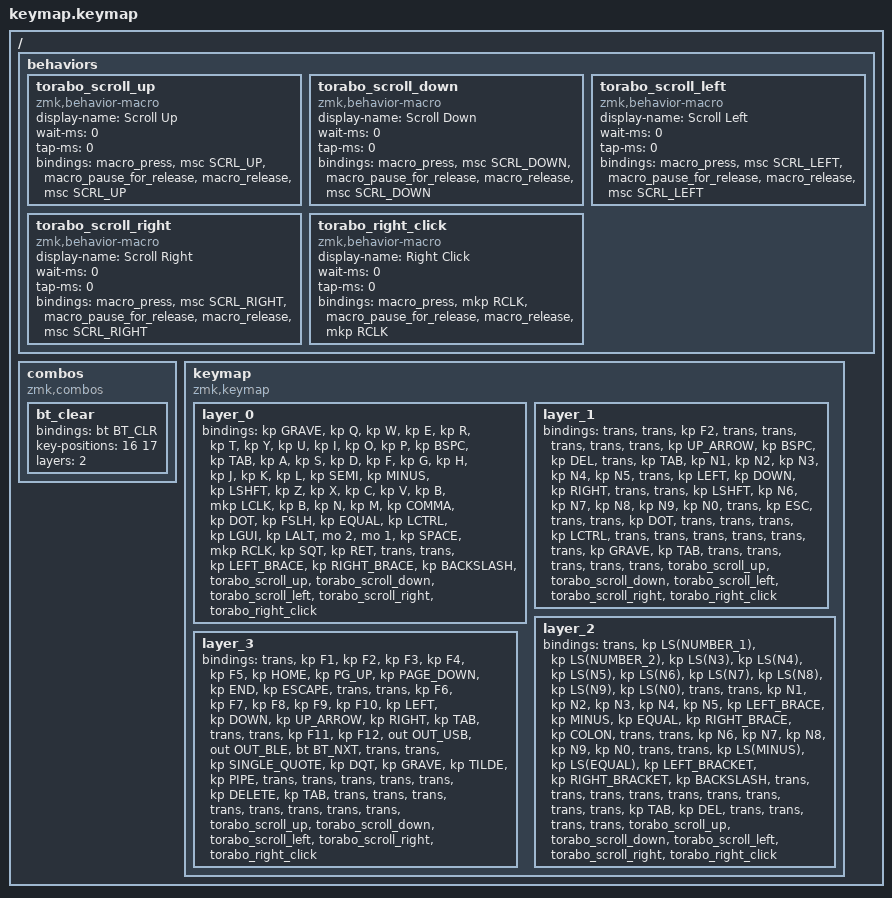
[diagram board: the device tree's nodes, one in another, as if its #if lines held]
#if defined(TORABO_TSUKI_LP_KSCAN_4_DIRECTION_SWITCH)
// Three times the ZMK v0.3 default scroll speed of 10.
#define ZMK_POINTING_DEFAULT_SCRL_VAL 30
#endif

#include <behaviors.dtsi>
#include <dt-bindings/zmk/bt.h>
#include <dt-bindings/zmk/keys.h>
#include <dt-bindings/zmk/outputs.h>
#include <dt-bindings/zmk/pointing.h>

/ {
#if defined(TORABO_TSUKI_LP_KSCAN_4_DIRECTION_SWITCH)
    // ZMK v0.3's &msc has no Studio parameter metadata. Fixed, zero-parameter
    // macros expose all four directions and right click as editable choices.
    // Pause between press/release so tilting keeps scrolling and push can drag.
    behaviors {
        torabo_scroll_up: torabo_scroll_up {
            compatible = "zmk,behavior-macro";
            display-name = "Scroll Up";
            #binding-cells = <0>;
            wait-ms = <0>;
            tap-ms = <0>;
            bindings = <&macro_press &msc SCRL_UP>,
                       <&macro_pause_for_release>,
                       <&macro_release &msc SCRL_UP>;
        };

        torabo_scroll_down: torabo_scroll_down {
            compatible = "zmk,behavior-macro";
            display-name = "Scroll Down";
            #binding-cells = <0>;
            wait-ms = <0>;
            tap-ms = <0>;
            bindings = <&macro_press &msc SCRL_DOWN>,
                       <&macro_pause_for_release>,
                       <&macro_release &msc SCRL_DOWN>;
        };

        torabo_scroll_left: torabo_scroll_left {
            compatible = "zmk,behavior-macro";
            display-name = "Scroll Left";
            #binding-cells = <0>;
            wait-ms = <0>;
            tap-ms = <0>;
            bindings = <&macro_press &msc SCRL_LEFT>,
                       <&macro_pause_for_release>,
                       <&macro_release &msc SCRL_LEFT>;
        };

        torabo_scroll_right: torabo_scroll_right {
            compatible = "zmk,behavior-macro";
            display-name = "Scroll Right";
            #binding-cells = <0>;
            wait-ms = <0>;
            tap-ms = <0>;
            bindings = <&macro_press &msc SCRL_RIGHT>,
                       <&macro_pause_for_release>,
                       <&macro_release &msc SCRL_RIGHT>;
        };

        torabo_right_click: torabo_right_click {
            compatible = "zmk,behavior-macro";
            display-name = "Right Click";
            #binding-cells = <0>;
            wait-ms = <0>;
            tap-ms = <0>;
            bindings = <&macro_press &mkp RCLK>,
                       <&macro_pause_for_release>,
                       <&macro_release &mkp RCLK>;
        };
    };
#endif

    combos {
        compatible = "zmk,combos";

        bt_clear {
            bindings = <&bt BT_CLR>;
            key-positions = <16 17>;
            layers = <2>;
        };
    };

    keymap {
        compatible = "zmk,keymap";

        layer_0 {
            bindings = <
                &kp GRAVE  &kp Q  &kp W  &kp E  &kp R  &kp T  &kp Y  &kp U  &kp I  &kp O  &kp P  &kp BSPC
                &kp TAB  &kp A  &kp S  &kp D  &kp F  &kp G  &kp H  &kp J  &kp K  &kp L  &kp SEMI  &kp MINUS
                &kp LSHFT  &kp Z  &kp X  &kp C  &kp V  &kp B  &mkp LCLK  &kp B  &kp N  &kp M  &kp COMMA  &kp DOT  &kp FSLH  &kp EQUAL
                &kp LCTRL  &kp LGUI  &kp LALT  &mo 2  &mo 1  &kp SPACE  &mkp RCLK  &kp SQT  &kp RET  &trans  &trans  &kp LEFT_BRACE  &kp RIGHT_BRACE  &kp BACKSLASH
#if defined(TORABO_TSUKI_LP_KSCAN_4_DIRECTION_SWITCH)
                // Additional positions 52..56: up, down, left, right, push.
                &torabo_scroll_up  &torabo_scroll_down  &torabo_scroll_left  &torabo_scroll_right  &torabo_right_click
#endif
            >;
        };

        layer_1 {
            bindings = <
                &trans  &trans  &kp F2  &trans  &trans  &trans  &trans  &trans  &kp UP_ARROW  &kp BSPC  &kp DEL  &trans
                &kp TAB  &kp N1  &kp N2  &kp N3  &kp N4  &kp N5  &trans  &kp LEFT  &kp DOWN  &kp RIGHT  &trans  &trans
                &kp LSHFT  &kp N6  &kp N7  &kp N8  &kp N9  &kp N0  &trans  &kp ESC  &trans  &trans  &kp DOT  &trans  &trans  &trans
                &kp LCTRL  &trans  &trans  &trans  &trans  &trans  &trans  &kp GRAVE  &kp TAB  &trans  &trans  &trans  &trans  &trans
#if defined(TORABO_TSUKI_LP_KSCAN_4_DIRECTION_SWITCH)
                &torabo_scroll_up  &torabo_scroll_down  &torabo_scroll_left  &torabo_scroll_right  &torabo_right_click
#endif
            >;
        };

        layer_2 {
            bindings = <
                &trans  &kp LS(NUMBER_1)  &kp LS(NUMBER_2)  &kp LS(N3)  &kp LS(N4)  &kp LS(N5)  &kp LS(N6)  &kp LS(N7)  &kp LS(N8)  &kp LS(N9)  &kp LS(N0)  &trans
                &trans  &kp N1  &kp N2  &kp N3  &kp N4  &kp N5  &kp LEFT_BRACE  &kp MINUS  &kp EQUAL  &kp RIGHT_BRACE  &kp COLON  &trans
                &trans  &kp N6  &kp N7  &kp N8  &kp N9  &kp N0  &trans  &trans  &kp LS(MINUS)  &kp LS(EQUAL)  &kp LEFT_BRACKET  &kp RIGHT_BRACKET  &kp BACKSLASH  &trans
                &trans  &trans  &trans  &trans  &trans  &trans  &trans  &trans  &kp TAB  &kp DEL  &trans  &trans  &trans  &trans
#if defined(TORABO_TSUKI_LP_KSCAN_4_DIRECTION_SWITCH)
                &torabo_scroll_up  &torabo_scroll_down  &torabo_scroll_left  &torabo_scroll_right  &torabo_right_click
#endif
            >;
        };

        layer_3 {
            bindings = <
                &trans  &kp F1  &kp F2  &kp F3  &kp F4  &kp F5  &kp HOME  &kp PG_UP  &kp PAGE_DOWN  &kp END  &kp ESCAPE  &trans
                &trans  &kp F6  &kp F7  &kp F8  &kp F9  &kp F10  &kp LEFT  &kp DOWN  &kp UP_ARROW  &kp RIGHT  &kp TAB  &trans
                &trans  &kp F11  &kp F12  &out OUT_USB  &out OUT_BLE  &bt BT_NXT  &trans  &trans  &kp SINGLE_QUOTE  &kp DQT  &kp GRAVE  &kp TILDE  &kp PIPE  &trans
                &trans  &trans  &trans  &trans  &kp DELETE  &kp TAB  &trans  &trans  &trans  &trans  &trans  &trans  &trans  &trans
#if defined(TORABO_TSUKI_LP_KSCAN_4_DIRECTION_SWITCH)
                &torabo_scroll_up  &torabo_scroll_down  &torabo_scroll_left  &torabo_scroll_right  &torabo_right_click
#endif
            >;
        };
    };
};
